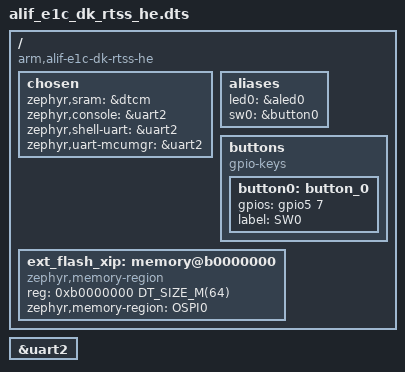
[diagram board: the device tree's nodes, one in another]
/* Copyright (c) 2024 Alif Semiconductor
 *
 * SPDX-License-Identifier: Apache-2.0
 */
/dts-v1/;

#include <alif/ensemble_e1c_rtss.dtsi>
#include <alif/ensemble-e1c-pinctrl.dtsi>

/ {
	compatible = "arm,alif-e1c-dk-rtss-he";
	#address-cells = <1>;
	#size-cells = <1>;

	chosen {
		zephyr,sram = &dtcm;
		zephyr,console = &uart2;
		zephyr,shell-uart = &uart2;
		zephyr,uart-mcumgr = &uart2;
	};

	aliases {
		led0 = &aled0;
		sw0 = &button0;
	};
	buttons {
		compatible = "gpio-keys";
		button0: button_0 {
			gpios = < &gpio5 7 0 >;
			label = "SW0";
		};
	};
	ext_flash_xip: memory@b0000000 {
		compatible = "zephyr,memory-region";
		reg = <0xb0000000 DT_SIZE_M(64)>;
		zephyr,memory-region = "OSPI0";
	};
};

&uart2 {
	status = "okay";
};
